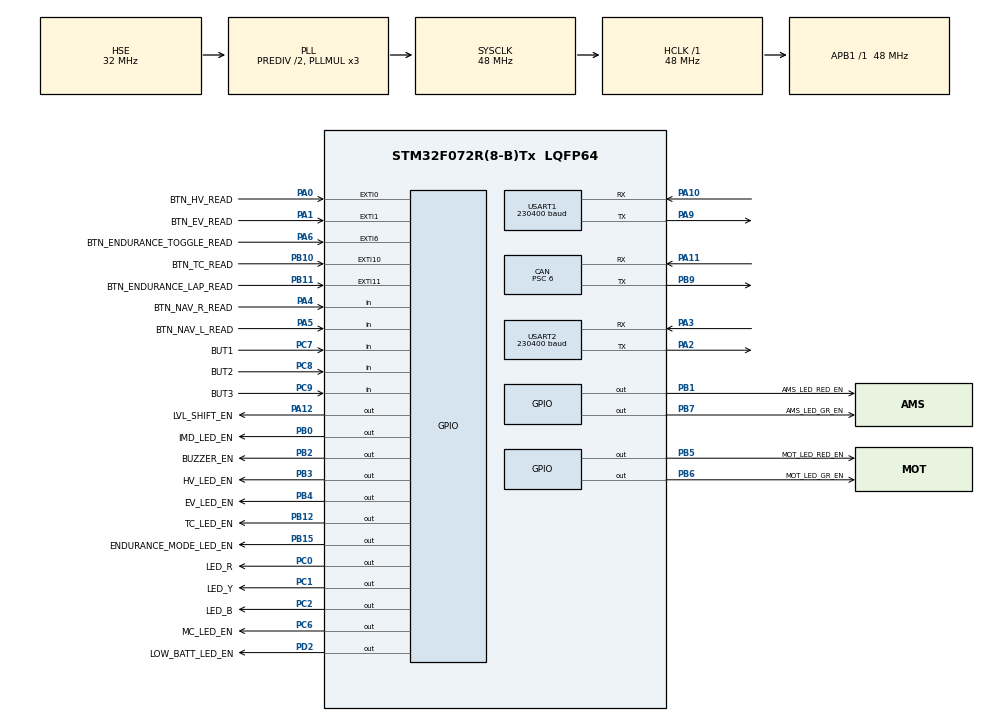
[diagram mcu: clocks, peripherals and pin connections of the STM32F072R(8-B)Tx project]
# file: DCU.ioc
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CAN.ABOM=ENABLE
CAN.AWUM=ENABLE
CAN.BS1=CAN_BS1_11TQ
CAN.BS2=CAN_BS2_4TQ
CAN.CalculateBaudRate=500000
CAN.CalculateTimeBit=2000
CAN.CalculateTimeQuantum=125.0
CAN.NART=ENABLE
CAN.Prescaler=6
CAN.SJW=CAN_SJW_4TQ
Dma.Request0=USART2_RX
Dma.USART2_RX.0.Direction=DMA_PERIPH_TO_MEMORY
Dma.USART2_RX.0.Instance=DMA1_Channel5
Dma.USART2_RX.0.MemDataAlignment=DMA_MDATAALIGN_BYTE
Dma.USART2_RX.0.MemInc=DMA_MINC_ENABLE
Dma.USART2_RX.0.Mode=DMA_CIRCULAR
Dma.USART2_RX.0.PeriphDataAlignment=DMA_PDATAALIGN_BYTE
Dma.USART2_RX.0.PeriphInc=DMA_PINC_DISABLE
Dma.USART2_RX.0.Priority=DMA_PRIORITY_LOW
FREERTOS.INCLUDE_vTaskDelayUntil=1
FREERTOS.Tasks01=mainTask,2,512,mainTaskFunction,As weak,NULL,Dynamic,NULL,NULL;watchdogTaskNam,3,160,watchdogTask,As external,NULL,Dynamic,NULL,NULL;printTaskName,-2,128,printTask,As external,NULL,Dynamic,NULL,NULL;cliTaskName,-2,512,cliTask,As external,NULL,Dynamic,NULL,NULL;led,0,100,ledTask,As external,NULL,Dynamic,NULL,NULL;canSendTask,3,256,canTask,As external,NULL,Dynamic,NULL,NULL
FREERTOS.configCHECK_FOR_STACK_OVERFLOW=2
FREERTOS.configGENERATE_RUN_TIME_STATS=1
FREERTOS.configMINIMAL_STACK_SIZE=64
FREERTOS.configTOTAL_HEAP_SIZE=10000
FREERTOS.configUSE_COUNTING_SEMAPHORES=1
FREERTOS.configUSE_STATS_FORMATTING_FUNCTIONS=1
FREERTOS.configUSE_TIMERS=1
FREERTOS.configUSE_TRACE_FACILITY=1
IWDG.Reload=400
Mcu.Family=STM32F0
Mcu.Name=STM32F072R(8-B)Tx
Mcu.Package=LQFP64
NVIC.CEC_CAN_IRQn=true\:3\:0\:false\:false\:true\:true\:true\:true\:true
NVIC.DMA1_Channel4_5_6_7_IRQn=true\:3\:0\:false\:false\:true\:true\:true\:true\:true
NVIC.EXTI0_1_IRQn=true\:3\:0\:false\:false\:true\:true\:true\:true\:true
NVIC.EXTI4_15_IRQn=true\:3\:0\:false\:false\:true\:true\:true\:true\:true
NVIC.USART2_IRQn=true\:3\:0\:false\:false\:true\:true\:true\:true\:true
PA0.GPIO_Label=BTN_HV_READ
PA0.GPIO_ModeDefaultEXTI=GPIO_MODE_IT_FALLING
PA0.GPIO_PuPd=GPIO_PULLUP
PA0.Signal=GPXTI0
PA1.GPIO_Label=BTN_EV_READ
PA1.GPIO_ModeDefaultEXTI=GPIO_MODE_IT_FALLING
PA1.GPIO_PuPd=GPIO_PULLUP
PA1.Signal=GPXTI1
PA10.Mode=Asynchronous
PA10.Signal=USART1_RX
PA11.Mode=CAN_Activate
PA11.Signal=CAN_RX
PA12.GPIO_Label=LVL_SHIFT_EN
PA12.Signal=GPIO_Output
PA13.Mode=Serial_Wire
PA13.Signal=SYS_SWDIO
PA14.Mode=Serial_Wire
PA14.Signal=SYS_SWCLK
PA2.Mode=Asynchronous
PA2.Signal=USART2_TX
PA3.Mode=Asynchronous
PA3.Signal=USART2_RX
PA4.GPIO_Label=BTN_NAV_R_READ
PA4.Signal=GPIO_Input
PA5.GPIO_Label=BTN_NAV_L_READ
PA5.Signal=GPIO_Input
PA6.GPIO_Label=BTN_ENDURANCE_TOGGLE_READ
PA6.GPIO_ModeDefaultEXTI=GPIO_MODE_IT_FALLING
PA6.GPIO_PuPd=GPIO_PULLUP
PA6.Signal=GPXTI6
PA9.Mode=Asynchronous
PA9.Signal=USART1_TX
PB0.GPIO_Label=IMD_LED_EN
PB0.Signal=GPIO_Output
PB1.GPIO_Label=AMS_LED_RED_EN
PB1.Signal=GPIO_Output
PB10.GPIO_Label=BTN_TC_READ
PB10.GPIO_ModeDefaultEXTI=GPIO_MODE_IT_FALLING
PB10.GPIO_PuPd=GPIO_PULLUP
PB10.Signal=GPXTI10
PB11.GPIO_Label=BTN_ENDURANCE_LAP_READ
PB11.GPIO_ModeDefaultEXTI=GPIO_MODE_IT_FALLING
PB11.GPIO_PuPd=GPIO_PULLUP
PB11.Signal=GPXTI11
PB12.GPIO_Label=TC_LED_EN
PB12.Signal=GPIO_Output
PB15.GPIO_Label=ENDURANCE_MODE_LED_EN
PB15.Signal=GPIO_Output
PB2.GPIO_Label=BUZZER_EN
PB2.Signal=GPIO_Output
PB3.GPIO_Label=HV_LED_EN
PB3.Signal=GPIO_Output
PB4.GPIO_Label=EV_LED_EN
PB4.Signal=GPIO_Output
PB5.GPIO_Label=MOT_LED_RED_EN
PB5.Signal=GPIO_Output
PB6.GPIO_Label=MOT_LED_GR_EN
PB6.Signal=GPIO_Output
PB7.GPIO_Label=AMS_LED_GR_EN
PB7.Signal=GPIO_Output
PB9.Mode=CAN_Activate
PB9.Signal=CAN_TX
PC0.GPIO_Label=LED_R
PC0.Signal=GPIO_Output
PC1.GPIO_Label=LED_Y
PC1.Signal=GPIO_Output
PC2.GPIO_Label=LED_B
PC2.Signal=GPIO_Output
PC6.GPIO_Label=MC_LED_EN
PC6.Signal=GPIO_Output
PC7.GPIO_Label=BUT1
PC7.Signal=GPIO_Input
PC8.GPIO_Label=BUT2
PC8.Signal=GPIO_Input
PC9.GPIO_Label=BUT3
PC9.Signal=GPIO_Input
PD2.GPIO_Label=LOW_BATT_LED_EN
PD2.Signal=GPIO_Output
PF0-OSC_IN.Mode=HSE-External-Oscillator
PF0-OSC_IN.Signal=RCC_OSC_IN
PF1-OSC_OUT.Mode=HSE-External-Oscillator
PF1-OSC_OUT.Signal=RCC_OSC_OUT
ProjectManager.HeapSize=0x200
ProjectManager.StackSize=0x400
ProjectManager.TargetToolchain=Makefile
RCC.AHBFreq_Value=48000000
RCC.APB1Freq_Value=48000000
RCC.APB1TimFreq_Value=48000000
RCC.HCLKFreq_Value=48000000
RCC.HSE_VALUE=32000000
RCC.PLLDivider=RCC_PREDIV_DIV2
RCC.PLLMUL=RCC_PLL_MUL3
RCC.PLLSourceVirtual=RCC_PLLSOURCE_HSE
RCC.SYSCLKFreq_VALUE=48000000
RCC.SYSCLKSource=RCC_SYSCLKSOURCE_PLLCLK
USART1.BaudRate=230400
USART1.VirtualMode-Asynchronous=VM_ASYNC
USART2.BaudRate=230400
USART2.VirtualMode-Asynchronous=VM_ASYNC
VP_FREERTOS_VS_CMSIS_V1.Mode=CMSIS_V1
VP_IWDG_VS_IWDG.Mode=IWDG_Activate
VP_TIM2_VS_ClockSourceINT.Mode=Internal
board=custom

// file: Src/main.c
/* USER CODE BEGIN Header */
/**
  ******************************************************************************
  * @file           : main.c
  * @brief          : Main program body
  ******************************************************************************
  ** This notice applies to any and all portions of this file
  * that are not between comment pairs USER CODE BEGIN and
  * USER CODE END. Other portions of this file, whether
  * inserted by the user or by software development tools
  * are owned by their respective copyright owners.
  *
  * COPYRIGHT(c) 2019 STMicroelectronics
  *
  * Redistribution and use in source and binary forms, with or without modification,
  * are permitted provided that the following conditions are met:
  *   1. Redistributions of source code must retain the above copyright notice,
  *      this list of conditions and the following disclaimer.
  *   2. Redistributions in binary form must reproduce the above copyright notice,
  *      this list of conditions and the following disclaimer in the documentation
  *      and/or other materials provided with the distribution.
  *   3. Neither the name of STMicroelectronics nor the names of its contributors
  *      may be used to endorse or promote products derived from this software
  *      without specific prior written permission.
  *
  * THIS SOFTWARE IS PROVIDED BY THE COPYRIGHT HOLDERS AND CONTRIBUTORS "AS IS"
  * AND ANY EXPRESS OR IMPLIED WARRANTIES, INCLUDING, BUT NOT LIMITED TO, THE
  * IMPLIED WARRANTIES OF MERCHANTABILITY AND FITNESS FOR A PARTICULAR PURPOSE ARE
  * DISCLAIMED. IN NO EVENT SHALL THE COPYRIGHT HOLDER OR CONTRIBUTORS BE LIABLE
  * FOR ANY DIRECT, INDIRECT, INCIDENTAL, SPECIAL, EXEMPLARY, OR CONSEQUENTIAL
  * DAMAGES (INCLUDING, BUT NOT LIMITED TO, PROCUREMENT OF SUBSTITUTE GOODS OR
  * SERVICES; LOSS OF USE, DATA, OR PROFITS; OR BUSINESS INTERRUPTION) HOWEVER
  * CAUSED AND ON ANY THEORY OF LIABILITY, WHETHER IN CONTRACT, STRICT LIABILITY,
  * OR TORT (INCLUDING NEGLIGENCE OR OTHERWISE) ARISING IN ANY WAY OUT OF THE USE
  * OF THIS SOFTWARE, EVEN IF ADVISED OF THE POSSIBILITY OF SUCH DAMAGE.
  *
  ******************************************************************************
  */
/* USER CODE END Header */
#include "main.h"
#include "cmsis_os.h"
#include "can.h"
#include "dma.h"
#include "iwdg.h"
#include "tim.h"
#include "usart.h"
#include "gpio.h"

/* USER CODE BEGIN Includes */
#include "watchdog.h"
#include "generalErrorHandler.h"
#include "stdio.h"
/* USER CODE END Includes */

/* USER CODE BEGIN PV */
/* Private variables ---------------------------------------------------------*/

/* USER CODE END PV */

void SystemClock_Config(void);
void MX_FREERTOS_Init(void);
/* USER CODE BEGIN PFP */
/* Private function prototypes -----------------------------------------------*/
__weak void userInit() {}

/* USER CODE END PFP */

int main(void)
{
  /* USER CODE BEGIN 1 */
  checkForWDReset();
  /* USER CODE END 1 */

  /* MCU Configuration--------------------------------------------------------*/

  /* Reset of all peripherals, Initializes the Flash interface and the Systick. */
  HAL_Init();

  /* Configure the system clock */
  SystemClock_Config();

  /* Initialize all configured peripherals */
  MX_GPIO_Init();
  MX_DMA_Init();
  MX_USART2_UART_Init();
  MX_CAN_Init();
  MX_USART1_UART_Init();
  MX_TIM2_Init();
  MX_IWDG_Init();
  /* USER CODE BEGIN 2 */
  userInit();
  printWDResetState();
  handleWatchdogReset();
  /* USER CODE END 2 */

  /* Call init function for freertos objects (in freertos.c) */
  MX_FREERTOS_Init();
  /* Start scheduler */
  osKernelStart();

  /* We should never get here as control is now taken by the scheduler */
  /* Infinite loop */
  while (1)
  {

  }
}

void SystemClock_Config(void)
{
  RCC_OscInitTypeDef RCC_OscInitStruct = {0};
  RCC_ClkInitTypeDef RCC_ClkInitStruct = {0};
  RCC_PeriphCLKInitTypeDef PeriphClkInit = {0};

  /** Initializes the RCC Oscillators according to the specified parameters
  * in the RCC_OscInitTypeDef structure.
  */
  RCC_OscInitStruct.OscillatorType = RCC_OSCILLATORTYPE_LSI|RCC_OSCILLATORTYPE_HSE;
  RCC_OscInitStruct.HSEState = RCC_HSE_ON;
  RCC_OscInitStruct.LSIState = RCC_LSI_ON;
  RCC_OscInitStruct.PLL.PLLState = RCC_PLL_ON;
  RCC_OscInitStruct.PLL.PLLSource = RCC_PLLSOURCE_HSE;
  RCC_OscInitStruct.PLL.PLLMUL = RCC_PLL_MUL3;
  RCC_OscInitStruct.PLL.PREDIV = RCC_PREDIV_DIV2;
  if (HAL_RCC_OscConfig(&RCC_OscInitStruct) != HAL_OK)
  {
    Error_Handler();
  }
  /** Initializes the CPU, AHB and APB buses clocks
  */
  RCC_ClkInitStruct.ClockType = RCC_CLOCKTYPE_HCLK|RCC_CLOCKTYPE_SYSCLK
                              |RCC_CLOCKTYPE_PCLK1;
  RCC_ClkInitStruct.SYSCLKSource = RCC_SYSCLKSOURCE_PLLCLK;
  RCC_ClkInitStruct.AHBCLKDivider = RCC_SYSCLK_DIV1;
  RCC_ClkInitStruct.APB1CLKDivider = RCC_HCLK_DIV1;

  if (HAL_RCC_ClockConfig(&RCC_ClkInitStruct, FLASH_LATENCY_1) != HAL_OK)
  {
    Error_Handler();
  }
  PeriphClkInit.PeriphClockSelection = RCC_PERIPHCLK_USART1|RCC_PERIPHCLK_USART2;
  PeriphClkInit.Usart1ClockSelection = RCC_USART1CLKSOURCE_PCLK1;
  PeriphClkInit.Usart2ClockSelection = RCC_USART2CLKSOURCE_PCLK1;
  if (HAL_RCCEx_PeriphCLKConfig(&PeriphClkInit) != HAL_OK)
  {
    Error_Handler();
  }
}

void HAL_TIM_PeriodElapsedCallback(TIM_HandleTypeDef *htim)
{
  if (htim->Instance == TIM1) {
    HAL_IncTick();
  }
}

void Error_Handler(void)
{
  /* USER CODE BEGIN Error_Handler_Debug */
  /* User can add his own implementation to report the HAL error return state */
  _handleError(__FILE__, __LINE__);
  /* USER CODE END Error_Handler_Debug */
}

#ifdef  USE_FULL_ASSERT
/**
  * @brief  Reports the name of the source file and the source line number
  *         where the assert_param error has occurred.
  * @param  file: pointer to the source file name
  * @param  line: assert_param error line source number
  * @retval None
  */
void assert_failed(uint8_t *file, uint32_t line)
{
  /* USER CODE BEGIN 6 */
  /* User can add his own implementation to report the file name and line number,
     tex: printf("Wrong parameters value: file %s on line %d\r\n", file, line) */
  printf("Wrong parameters value: file %s on line %ld\r\n", file, line);
  /* USER CODE END 6 */
}
#endif /* USE_FULL_ASSERT */

/************************ (C) COPYRIGHT STMicroelectronics *****END OF FILE****/
